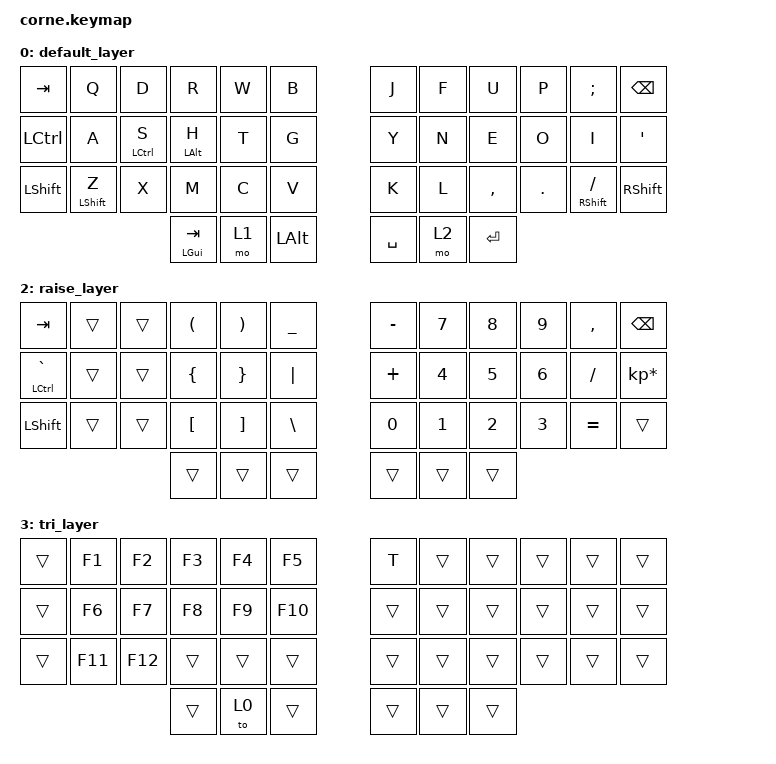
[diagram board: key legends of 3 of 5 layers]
/*
 * Copyright (c) 2020 The ZMK Contributors
 *
 * SPDX-License-Identifier: MIT
 */

#include <behaviors.dtsi>
#include <dt-bindings/zmk/keys.h>
#include <dt-bindings/zmk/bt.h>

&mt {
    flavor = "tap-preferred";
    tapping_term_ms = <200>;
};

/ {
    combos {
        compatible = "zmk,combos";
        esc {
            timeout-ms = <40>;
            key-positions = <2 3>;
            bindings = <&kp ESC>;
        };
        
        // ent {
        //     timeout-ms = <40>;
	    //     key-positions = <27 28>;
        //     bindings = <&kp RET>;
        // };

        bspc {
            timeout-ms = <40>;
	        key-positions = <8 9>;
            bindings = <&kp BSPC>;
        };
        
        // lalt {
        //     timeout-ms = <40>;
        //     key-positions = <11 12>;
        //     bindings = <&kp LALT>;
        // };

        to_bt {
            timeout-ms = <40>;
            key-positions = <1 10>;
            bindings = <&to 4>;
        };

        sl_fn {
            timeout-ms = <40>;
            key-positions = <13 22>;
            bindings = <&sl 3>;
        };

        to0 {
            timeout-ms = <40>;
            key-positions = <2 3 4>;
            bindings = <&to 0>;
        };

        sl2 {
            timeout-ms = <40>;
            key-positions = <7 8 9>;
            bindings = <&sl 2>;
        };

        sl1 {
            timeout-ms = <40>;
            key-positions = <27 28>;
            bindings = <&sl 1>;
        };         
    };

        
        behaviors {
            hm: homerow_mods {
                compatible = "zmk,behavior-hold-tap";
                label = "homerow mods";
                #binding-cells = <2>;
                tapping_term_ms = <200>;
                quick_tap_ms = <0>;
                flavor = "tap-preferred";
                bindings = <&kp>, <&kp>;
            };
            hs: homerow_shifts {
                compatible = "zmk,behavior-hold-tap";
                label = "HOMEROW_SHIFTS";
                #binding-cells = <2>;
                tapping-term-ms = <150>;
                quick_tap_ms = <0>;
                flavor = "balanced";
                bindings = <&kp>, <&kp>;
            };
            hsl: homerow_shifts_layer {
                compatible = "zmk,behavior-hold-tap";
                label = "HOMEROW_SHIFTS_LAYER";
                #binding-cells = <2>;
                tapping-term-ms = <150>;
                quick_tap_ms = <0>;
                flavor = "balanced";
                bindings = <&kp>, <&to>;
            };
            td: tapdance {
                compatible = "zmk,behavior-hold-tap";
                label = "TAPDANCE";
                #binding-cells = <2>;
                tapping-term-ms = <150>;
                quick_tap_ms = <0>;
                flavor = "tap-preferred";
                bindings = <&kp>, <&kp>;
            };
        };
            
        keymap {
            compatible = "zmk,keymap";

            default_layer {
                bindings = <
        &kp TAB   &kp Q        &kp D       &kp R      &kp W &kp B     &kp J &kp F  &kp U     &kp P   &kp SEMI        &kp BSPC
        &kp LCTRL &kp A        &hm LCTRL S &hm LALT H &kp T &kp G     &kp Y &kp N  &kp E     &kp O   &kp I           &kp SQT
        &kp LSHFT &hs LSHIFT Z &kp X       &kp M      &kp C &kp V     &kp K &kp L  &kp COMMA &kp DOT &hs RSHIFT FSLH &kp RSHFT
                                      &mt LGUI TAB &mo 1 &kp LALT     &kp SPACE &mo 2 &kp RET
                        >;
                };
                
            lower_layer {
                bindings = <
        &kp ESC   &kp BANG         &kp ATSN         &kp HASH         &kp DLLR        &kp PRCT    			&kp CRRT  &kp AMPS  &kp KMLT &kp LPRN  &kp RPRN &kp BSPC
        &kp LCTRL &kp LS(LA(DOWN)) &kp LS(LA(DOWN)) &hm LALT F12     &kp F2          &kp LG(LS(LC(N4))) 	&kp LEFT  &kp DOWN  &kp UP   &kp RIGHT &kp QUOT &kp GRAVE
        &kp LSHFT &hs LSFT GRAVE   &kp TILDE 	    &kp NON_US_BSLH  &kp LG(LA(C))   &kp LG(LS(LA(V)))      &kp UNDER &kp LEFT  &kp DOWN &kp RIGHT &kp PIPE &trans
                                                          &trans   &trans  &trans         &trans    &trans   &trans
                        >;
                };
                
            raise_layer {
                bindings = <
        &kp TAB         &trans &trans &kp LPAR    &kp RPAR &kp UNDER       &kp MINUS &kp N7   &kp N8 &kp N9  &kp COMMA &kp BSPC
        &hm LCTRL GRAVE &trans &trans &kp LBRC    &kp RBRC &kp PIPE        &kp PLUS  &kp N4   &kp N5 &kp N6  &kp FSLH  &kp KP_MULTIPLY
        &kp LSHFT       &trans &trans &kp LBKT    &kp RBKT &kp BSLH        &kp N0    &kp N1   &kp N2 &kp N3  &kp EQUAL &trans
                                          &trans     &trans   &trans       &trans    &trans   &trans
                        >;
                };

            tri_layer {
                bindings = <
            &trans &kp F1 &kp F2   &kp F3 &kp F4 &kp F5  	&kp T  &trans  &trans &trans &trans &trans
            &trans &kp F6 &kp F7   &kp F8 &kp F9 &kp F10    &trans &trans  &trans &trans &trans &trans  
            &trans &kp F11 &kp F12 &trans &trans &trans 	&trans &trans  &trans &trans &trans &trans
                                    &trans &to 0 &trans  	&trans &trans &trans
                >;
            };

            bt {
                bindings = <
        &kp TAB    &bt BT_CLR   &bt BT_SEL 0 &kp LPAR  &kp RPAR &kp UNDER     &kp B &trans  &trans  &trans  &kp DOT   &kp BSPC
        &bt BT_NXT &bt BT_SEL 1 &bt BT_SEL 2 &kp LBKT  &kp RBKT &kp PIPE      &kp PLUS  &kp PG_UP  &kp K_VOL_UP &kp K_MUTE  &kp FSLH  &kp LG(LS(LC(N4)))
        &kp LSHFT  &bt BT_SEL 3 &bt BT_SEL 4 &kp LBRC  &kp RBRC &kp BSLH      &trans    &kp PG_UP  &kp K_VOL_UP &kp K_MUTE  &trans  &kp EQUAL &trans
                                                &trans    &to 0   &trans      &trans    &to 0    &trans
                    >;
            };
        };
};
